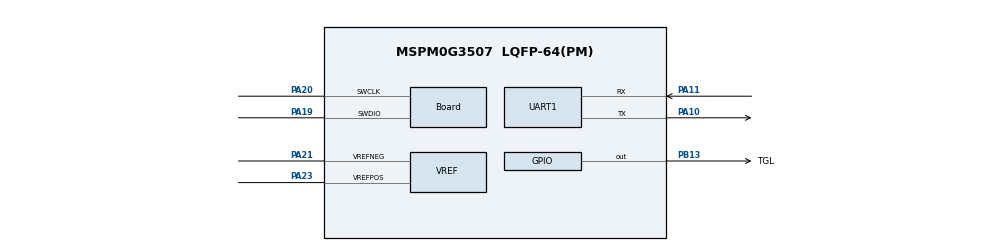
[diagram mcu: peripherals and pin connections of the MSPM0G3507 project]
//@cliArgs --device "MSPM0G350X" --package "LQFP-64(PM)" --part "Default"
//@v2CliArgs --device "MSPM0G3507" --package "LQFP-64(PM)"
// @cliArgs --board /ti/boards/LP_MSPM0G3507 --rtos nortos

/**
 * Import the modules used in this configuration.
 */
const ADC12         = scripting.addModule("/ti/driverlib/ADC12", {}, false);
const ADC121        = ADC12.addInstance();
const Board         = scripting.addModule("/ti/driverlib/Board");
const DMA           = scripting.addModule("/ti/driverlib/DMA");
const GPIO          = scripting.addModule("/ti/driverlib/GPIO", {}, false);
const GPIO1         = GPIO.addInstance();
const SYSCTL        = scripting.addModule("/ti/driverlib/SYSCTL");
const TIMER         = scripting.addModule("/ti/driverlib/TIMER", {}, false);
const TIMER1        = TIMER.addInstance();
const UART          = scripting.addModule("/ti/driverlib/UART", {}, false);
const UART1         = UART.addInstance();
const VREF          = scripting.addModule("/ti/driverlib/VREF");
const ProjectConfig = scripting.addModule("/ti/project_config/ProjectConfig");

/**
 * Write custom configuration values to the imported modules.
 */
ADC121.$name                      = "ADC12_0";
ADC121.enabledInterrupts          = ["DL_ADC12_INTERRUPT_MEM0_RESULT_LOADED"];
ADC121.sampCnt                    = 1;
ADC121.enabledDMATriggers         = ["DL_ADC12_DMA_MEM0_RESULT_LOADED"];
ADC121.sampClkDiv                 = "DL_ADC12_CLOCK_DIVIDE_16";
ADC121.sampleTime0                = "40 us";
ADC121.trigSrc                    = "DL_ADC12_TRIG_SRC_EVENT";
ADC121.subChanID                  = 1;
ADC121.repeatMode                 = true;
ADC121.adcMem0trig                = "DL_ADC12_TRIGGER_MODE_TRIGGER_NEXT";
ADC121.adcMem0chansel             = "DL_ADC12_INPUT_CHAN_2";
ADC121.resolution                 = "DL_ADC12_SAMP_CONV_RES_8_BIT";
ADC121.peripheral.$assign         = "ADC0";
ADC121.peripheral.adcPin2.$assign = "PA25";
ADC121.adcPin2Config.$name        = "ti_driverlib_gpio_GPIOPinGeneric0";

Board.peripheral.$assign          = "DEBUGSS";
Board.peripheral.swclkPin.$assign = "PA20";
Board.peripheral.swdioPin.$assign = "PA19";

GPIO1.$name                         = "DEBUG";
GPIO1.associatedPins[0].$name       = "TGL";
GPIO1.associatedPins[0].pin.$assign = "PB13";

SYSCTL.forceDefaultClkConfig = true;
SYSCTL.clockTreeEn           = true;

TIMER1.timerMode                   = "PERIODIC";
TIMER1.timerClkDiv                 = 8;
TIMER1.timerClkPrescale            = 8;
TIMER1.event1PublisherChannel      = 1;
TIMER1.event1ControllerInterruptEn = ["ZERO_EVENT"];
TIMER1.$name                       = "SAMPLING_TIMER";
TIMER1.timerPeriod                 = "32ms";
TIMER1.peripheral.$assign          = "TIMA0";

UART1.targetBaudRate                      = 115200;
UART1.enabledDMATXTriggers                = "DL_UART_DMA_INTERRUPT_TX";
UART1.enabledDMARXTriggers                = "DL_UART_DMA_INTERRUPT_RX";
UART1.$name                               = "UART_DAP";
UART1.peripheral.$assign                  = "UART0";
UART1.peripheral.rxPin.$assign            = "PA11";
UART1.peripheral.txPin.$assign            = "PA10";
UART1.DMA_CHANNEL_TX.$name                = "DMA_CH1";
UART1.DMA_CHANNEL_TX.addressMode          = "b2f";
UART1.DMA_CHANNEL_TX.srcLength            = "BYTE";
UART1.DMA_CHANNEL_TX.dstLength            = "BYTE";
UART1.DMA_CHANNEL_TX.enableInterrupt      = true;
UART1.DMA_CHANNEL_TX.peripheral.$assign   = "DMA_CH1";
UART1.DMA_CHANNEL_RX.$name                = "DMA_CH0";
UART1.DMA_CHANNEL_RX.addressMode          = "f2b";
UART1.DMA_CHANNEL_RX.srcLength            = "BYTE";
UART1.DMA_CHANNEL_RX.dstLength            = "BYTE";
UART1.DMA_CHANNEL_RX.enableEarlyInterrupt = true;
UART1.DMA_CHANNEL_RX.earlyIntThresh       = "64";
UART1.DMA_CHANNEL_RX.peripheral.$assign   = "DMA_CH0";

VREF.basicVrefPins                 = "VREF+-";
VREF.basicExtVolt                  = 3.3;
VREF.basicMode                     = "DL_VREF_ENABLE_DISABLE";
VREF.peripheral.$assign            = "VREF";
VREF.peripheral.vrefPosPin.$assign = "PA23";
VREF.peripheral.vrefNegPin.$assign = "PA21";

ProjectConfig.migrationCondition = true;
